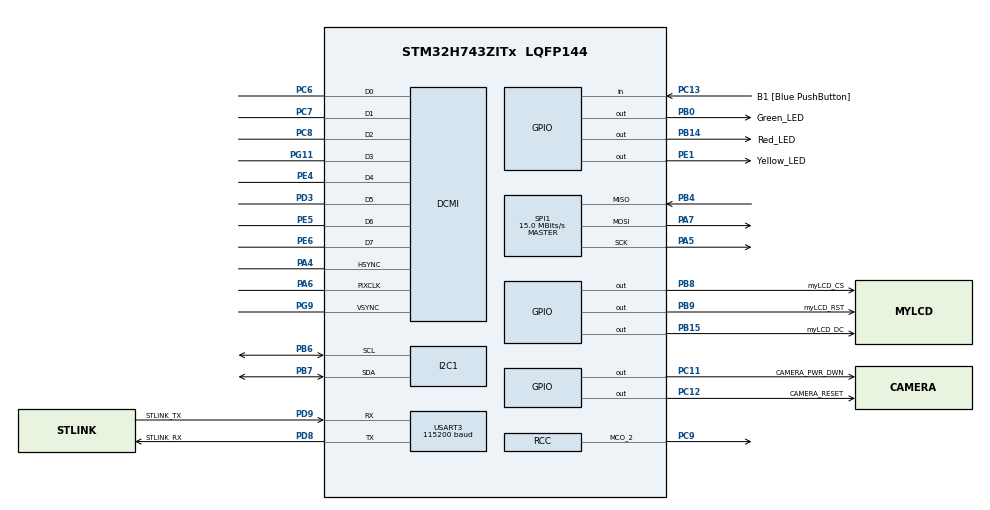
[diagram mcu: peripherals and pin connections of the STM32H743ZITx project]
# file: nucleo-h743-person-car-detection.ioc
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DCMI.ByteSelectMode=DCMI_BSM_ALTERNATE_2
DCMI.HSPolarity=DCMI_HSPOLARITY_LOW
DCMI.PCKPolarity=DCMI_PCKPOLARITY_RISING
DCMI.VSPolarity=DCMI_VSPOLARITY_HIGH
Dma.DCMI.0.Direction=DMA_PERIPH_TO_MEMORY
Dma.DCMI.0.EventEnable=DISABLE
Dma.DCMI.0.FIFOMode=DMA_FIFOMODE_DISABLE
Dma.DCMI.0.Instance=DMA1_Stream1
Dma.DCMI.0.MemDataAlignment=DMA_MDATAALIGN_WORD
Dma.DCMI.0.MemInc=DMA_MINC_ENABLE
Dma.DCMI.0.Mode=DMA_NORMAL
Dma.DCMI.0.PeriphDataAlignment=DMA_PDATAALIGN_WORD
Dma.DCMI.0.PeriphInc=DMA_PINC_DISABLE
Dma.DCMI.0.Polarity=HAL_DMAMUX_REQ_GEN_RISING
Dma.DCMI.0.Priority=DMA_PRIORITY_MEDIUM
Dma.DCMI.0.RequestNumber=1
Dma.DCMI.0.SignalID=NONE
Dma.DCMI.0.SyncEnable=DISABLE
Dma.DCMI.0.SyncPolarity=HAL_DMAMUX_SYNC_NO_EVENT
Dma.DCMI.0.SyncRequestNumber=1
Dma.DCMI.0.SyncSignalID=NONE
Dma.Request0=DCMI
I2C1.Timing=0x307075B1
Mcu.Family=STM32H7
Mcu.Name=STM32H743ZITx
Mcu.Package=LQFP144
NVIC.DCMI_IRQn=true\:0\:0\:false\:false\:true\:true\:true
NVIC.DMA1_Stream1_IRQn=true\:0\:0\:false\:false\:true\:false\:true
NVIC.PriorityGroup=NVIC_PRIORITYGROUP_4
PA4.Mode=Slave_8_bits_External_Synchro
PA4.Signal=DCMI_HSYNC
PA5.Mode=Full_Duplex_Master
PA5.Signal=SPI1_SCK
PA6.Mode=Slave_8_bits_External_Synchro
PA6.Signal=DCMI_PIXCLK
PA7.Mode=Full_Duplex_Master
PA7.Signal=SPI1_MOSI
PB0.GPIO_Label=Green_LED
PB0.Signal=GPIO_Output
PB14.GPIO_Label=Red_LED
PB14.Signal=GPIO_Output
PB15.GPIO_Label=myLCD_DC
PB15.Signal=GPIO_Output
PB4\ (NJTRST).Mode=Full_Duplex_Master
PB4\ (NJTRST).Signal=SPI1_MISO
PB6.GPIO_PuPd=GPIO_PULLUP
PB6.Mode=I2C
PB6.Signal=I2C1_SCL
PB7.GPIO_PuPd=GPIO_PULLUP
PB7.Mode=I2C
PB7.Signal=I2C1_SDA
PB8.GPIO_Label=myLCD_CS
PB8.GPIO_Speed=GPIO_SPEED_FREQ_VERY_HIGH
PB8.Signal=GPIO_Output
PB9.GPIO_Label=myLCD_RST
PB9.Signal=GPIO_Output
PC11.GPIO_Label=CAMERA_PWR_DWN
PC11.Signal=GPIO_Output
PC12.GPIO_Label=CAMERA_RESET
PC12.PinState=GPIO_PIN_SET
PC12.Signal=GPIO_Output
PC13.GPIO_Label=B1 [Blue PushButton]
PC13.Signal=GPIO_Input
PC14-OSC32_IN\ (OSC32_IN).Mode=LSE-External-Oscillator
PC14-OSC32_IN\ (OSC32_IN).Signal=RCC_OSC32_IN
PC15-OSC32_OUT\ (OSC32_OUT).Mode=LSE-External-Oscillator
PC15-OSC32_OUT\ (OSC32_OUT).Signal=RCC_OSC32_OUT
PC6.Mode=Slave_8_bits_External_Synchro
PC6.Signal=DCMI_D0
PC7.Mode=Slave_8_bits_External_Synchro
PC7.Signal=DCMI_D1
PC8.Mode=Slave_8_bits_External_Synchro
PC8.Signal=DCMI_D2
PC9.Mode=Clock-out-2
PC9.Signal=RCC_MCO_2
PD3.Mode=Slave_8_bits_External_Synchro
PD3.Signal=DCMI_D5
PD8.GPIO_Label=STLINK_RX
PD8.Mode=Asynchronous
PD8.Signal=USART3_TX
PD9.GPIO_Label=STLINK_TX
PD9.Mode=Asynchronous
PD9.Signal=USART3_RX
PE1.GPIO_Label=Yellow_LED
PE1.Signal=GPIO_Output
PE4.Mode=Slave_8_bits_External_Synchro
PE4.Signal=DCMI_D4
PE5.Mode=Slave_8_bits_External_Synchro
PE5.Signal=DCMI_D6
PE6.Mode=Slave_8_bits_External_Synchro
PE6.Signal=DCMI_D7
PG11.Mode=Slave_8_bits_External_Synchro
PG11.Signal=DCMI_D3
PG9.Mode=Slave_8_bits_External_Synchro
PG9.Signal=DCMI_VSYNC
PH0-OSC_IN\ (PH0).Mode=HSE-External-Clock-Source
PH0-OSC_IN\ (PH0).Signal=RCC_OSC_IN
PH1-OSC_OUT\ (PH1).Signal=RCC_OSC_OUT
ProjectManager.HeapSize=0x200
ProjectManager.StackSize=0x400
ProjectManager.TargetToolchain=STM32CubeIDE
RCC.ADCFreq_Value=50666666.666666664
RCC.APB1Freq_Value=120000000
RCC.APB2Freq_Value=120000000
RCC.APB3Freq_Value=120000000
RCC.APB4Freq_Value=120000000
RCC.CortexFreq_Value=480000000
RCC.D1PPRE=RCC_APB3_DIV2
RCC.D2PPRE1=RCC_APB1_DIV2
RCC.D2PPRE2=RCC_APB2_DIV2
RCC.D3PPRE=RCC_APB4_DIV2
RCC.DIVM1=1
RCC.DIVM2=1
RCC.DIVN1=120
RCC.DIVN2=19
RCC.DIVP2=3
RCC.HCLKFreq_Value=240000000
RCC.HPRE=RCC_HCLK_DIV2
RCC.HSE_VALUE=8000000
RCC.PLL2FRACN=0
RCC.PLL3FRACN=0
RCC.PLLFRACN=0
RCC.PLLSourceVirtual=RCC_PLLSOURCE_HSE
RCC.RCC_MCODiv2=RCC_MCODIV_15
RCC.SYSCLKFreq_VALUE=480000000
RCC.SYSCLKSource=RCC_SYSCLKSOURCE_PLLCLK
RCC.USBFreq_Value=480000000
SPI1.BaudRatePrescaler=SPI_BAUDRATEPRESCALER_32
SPI1.CalculateBaudRate=15.0 MBits/s
SPI1.DataSize=SPI_DATASIZE_8BIT
SPI1.Direction=SPI_DIRECTION_2LINES
SPI1.Mode=SPI_MODE_MASTER
SPI1.VirtualType=VM_MASTER
TIM2.Period=4294967295
TIM2.Prescaler=240-1
USART3.BaudRate=115200
USART3.VirtualMode-Asynchronous=VM_ASYNC
VP_TIM2_VS_ClockSourceINT.Mode=Internal
board=NUCLEO-H743ZI2

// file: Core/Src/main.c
/* USER CODE BEGIN Header */
/**
  ******************************************************************************
  * @file           : main.c
  * @brief          : Main program body
  ******************************************************************************
  * @attention
  *
  * <h2><center>&copy; Copyright (c) 2020 STMicroelectronics.
  * All rights reserved.</center></h2>
  *
  * This software component is licensed by ST under BSD 3-Clause license,
  * the "License"; You may not use this file except in compliance with the
  * License. You may obtain a copy of the License at:
  *                        opensource.org/licenses/BSD-3-Clause
  *
  ******************************************************************************
  */
/* USER CODE END Header */
#include "main.h"

/* USER CODE BEGIN Includes */
#include  <string.h>
#include "main_functions.h"

/* USER CODE END Includes */

DCMI_HandleTypeDef hdcmi;
DMA_HandleTypeDef hdma_dcmi;

I2C_HandleTypeDef hi2c1;

SPI_HandleTypeDef hspi1;

TIM_HandleTypeDef htim2;

UART_HandleTypeDef huart3;

void SystemClock_Config(void);
static void MX_GPIO_Init(void);
static void MX_DMA_Init(void);
static void MX_USART3_UART_Init(void);
static void MX_DCMI_Init(void);
static void MX_TIM2_Init(void);
static void MX_I2C1_Init(void);
static void MX_SPI1_Init(void);
/* USER CODE BEGIN PFP */
//static void onFrameCallback();
/* USER CODE END PFP */

int main(void)
{

  /* MCU Configuration--------------------------------------------------------*/

  /* Reset of all peripherals, Initializes the Flash interface and the Systick. */
  HAL_Init();

  /* Configure the system clock */
  SystemClock_Config();

  /* Initialize all configured peripherals */
  MX_GPIO_Init();
  MX_DMA_Init();
  MX_USART3_UART_Init();
  MX_DCMI_Init();
  MX_TIM2_Init();
  MX_I2C1_Init();
  MX_SPI1_Init();
  /* USER CODE BEGIN 2 */
  setup(&htim2, &huart3, &hdcmi, &hdma_dcmi, &hi2c1, &hspi1);
  /* USER CODE END 2 */

  /* Infinite loop */
  /* USER CODE BEGIN WHILE */
  while (1)
  {
	  loop(&htim2, &huart3, &hdcmi, &hdma_dcmi, &hi2c1, &hspi1);
    /* USER CODE END WHILE */

  }
}

void SystemClock_Config(void)
{
  RCC_OscInitTypeDef RCC_OscInitStruct = {0};
  RCC_ClkInitTypeDef RCC_ClkInitStruct = {0};
  RCC_PeriphCLKInitTypeDef PeriphClkInitStruct = {0};

  /** Supply configuration update enable
  */
  HAL_PWREx_ConfigSupply(PWR_LDO_SUPPLY);
  /** Configure the main internal regulator output voltage
  */
  __HAL_PWR_VOLTAGESCALING_CONFIG(PWR_REGULATOR_VOLTAGE_SCALE0);

  while(!__HAL_PWR_GET_FLAG(PWR_FLAG_VOSRDY)) {}
  /** Initializes the RCC Oscillators according to the specified parameters
  * in the RCC_OscInitTypeDef structure.
  */
  RCC_OscInitStruct.OscillatorType = RCC_OSCILLATORTYPE_HSE;
  RCC_OscInitStruct.HSEState = RCC_HSE_BYPASS;
  RCC_OscInitStruct.PLL.PLLState = RCC_PLL_ON;
  RCC_OscInitStruct.PLL.PLLSource = RCC_PLLSOURCE_HSE;
  RCC_OscInitStruct.PLL.PLLM = 1;
  RCC_OscInitStruct.PLL.PLLN = 120;
  RCC_OscInitStruct.PLL.PLLP = 2;
  RCC_OscInitStruct.PLL.PLLQ = 2;
  RCC_OscInitStruct.PLL.PLLR = 2;
  RCC_OscInitStruct.PLL.PLLRGE = RCC_PLL1VCIRANGE_3;
  RCC_OscInitStruct.PLL.PLLVCOSEL = RCC_PLL1VCOWIDE;
  RCC_OscInitStruct.PLL.PLLFRACN = 0;
  if (HAL_RCC_OscConfig(&RCC_OscInitStruct) != HAL_OK)
  {
    Error_Handler();
  }
  /** Initializes the CPU, AHB and APB buses clocks
  */
  RCC_ClkInitStruct.ClockType = RCC_CLOCKTYPE_HCLK|RCC_CLOCKTYPE_SYSCLK
                              |RCC_CLOCKTYPE_PCLK1|RCC_CLOCKTYPE_PCLK2
                              |RCC_CLOCKTYPE_D3PCLK1|RCC_CLOCKTYPE_D1PCLK1;
  RCC_ClkInitStruct.SYSCLKSource = RCC_SYSCLKSOURCE_PLLCLK;
  RCC_ClkInitStruct.SYSCLKDivider = RCC_SYSCLK_DIV1;
  RCC_ClkInitStruct.AHBCLKDivider = RCC_HCLK_DIV2;
  RCC_ClkInitStruct.APB3CLKDivider = RCC_APB3_DIV2;
  RCC_ClkInitStruct.APB1CLKDivider = RCC_APB1_DIV2;
  RCC_ClkInitStruct.APB2CLKDivider = RCC_APB2_DIV2;
  RCC_ClkInitStruct.APB4CLKDivider = RCC_APB4_DIV2;

  if (HAL_RCC_ClockConfig(&RCC_ClkInitStruct, FLASH_LATENCY_4) != HAL_OK)
  {
    Error_Handler();
  }
  PeriphClkInitStruct.PeriphClockSelection = RCC_PERIPHCLK_USART3|RCC_PERIPHCLK_SPI1
                              |RCC_PERIPHCLK_I2C1;
  PeriphClkInitStruct.Spi123ClockSelection = RCC_SPI123CLKSOURCE_PLL;
  PeriphClkInitStruct.Usart234578ClockSelection = RCC_USART234578CLKSOURCE_D2PCLK1;
  PeriphClkInitStruct.I2c123ClockSelection = RCC_I2C123CLKSOURCE_D2PCLK1;
  if (HAL_RCCEx_PeriphCLKConfig(&PeriphClkInitStruct) != HAL_OK)
  {
    Error_Handler();
  }
  HAL_RCC_MCOConfig(RCC_MCO2, RCC_MCO2SOURCE_SYSCLK, RCC_MCODIV_15);
}

static void MX_DCMI_Init(void)
{

  hdcmi.Instance = DCMI;
  hdcmi.Init.SynchroMode = DCMI_SYNCHRO_HARDWARE;
  hdcmi.Init.PCKPolarity = DCMI_PCKPOLARITY_RISING;
  hdcmi.Init.VSPolarity = DCMI_VSPOLARITY_HIGH;
  hdcmi.Init.HSPolarity = DCMI_HSPOLARITY_LOW;
  hdcmi.Init.CaptureRate = DCMI_CR_ALL_FRAME;
  hdcmi.Init.ExtendedDataMode = DCMI_EXTEND_DATA_8B;
  hdcmi.Init.JPEGMode = DCMI_JPEG_DISABLE;
  hdcmi.Init.ByteSelectMode = DCMI_BSM_ALTERNATE_2;
  hdcmi.Init.ByteSelectStart = DCMI_OEBS_ODD;
  hdcmi.Init.LineSelectMode = DCMI_LSM_ALL;
  hdcmi.Init.LineSelectStart = DCMI_OELS_ODD;
  if (HAL_DCMI_Init(&hdcmi) != HAL_OK)
  {
    Error_Handler();
  }

}

static void MX_I2C1_Init(void)
{

  hi2c1.Instance = I2C1;
  hi2c1.Init.Timing = 0x307075B1;
  hi2c1.Init.OwnAddress1 = 0;
  hi2c1.Init.AddressingMode = I2C_ADDRESSINGMODE_7BIT;
  hi2c1.Init.DualAddressMode = I2C_DUALADDRESS_DISABLE;
  hi2c1.Init.OwnAddress2 = 0;
  hi2c1.Init.OwnAddress2Masks = I2C_OA2_NOMASK;
  hi2c1.Init.GeneralCallMode = I2C_GENERALCALL_DISABLE;
  hi2c1.Init.NoStretchMode = I2C_NOSTRETCH_DISABLE;
  if (HAL_I2C_Init(&hi2c1) != HAL_OK)
  {
    Error_Handler();
  }
  /** Configure Analogue filter
  */
  if (HAL_I2CEx_ConfigAnalogFilter(&hi2c1, I2C_ANALOGFILTER_ENABLE) != HAL_OK)
  {
    Error_Handler();
  }
  /** Configure Digital filter
  */
  if (HAL_I2CEx_ConfigDigitalFilter(&hi2c1, 0) != HAL_OK)
  {
    Error_Handler();
  }

}

static void MX_SPI1_Init(void)
{

  /* SPI1 parameter configuration*/
  hspi1.Instance = SPI1;
  hspi1.Init.Mode = SPI_MODE_MASTER;
  hspi1.Init.Direction = SPI_DIRECTION_2LINES;
  hspi1.Init.DataSize = SPI_DATASIZE_8BIT;
  hspi1.Init.CLKPolarity = SPI_POLARITY_LOW;
  hspi1.Init.CLKPhase = SPI_PHASE_1EDGE;
  hspi1.Init.NSS = SPI_NSS_SOFT;
  hspi1.Init.BaudRatePrescaler = SPI_BAUDRATEPRESCALER_32;
  hspi1.Init.FirstBit = SPI_FIRSTBIT_MSB;
  hspi1.Init.TIMode = SPI_TIMODE_DISABLE;
  hspi1.Init.CRCCalculation = SPI_CRCCALCULATION_DISABLE;
  hspi1.Init.CRCPolynomial = 0x0;
  hspi1.Init.NSSPMode = SPI_NSS_PULSE_ENABLE;
  hspi1.Init.NSSPolarity = SPI_NSS_POLARITY_LOW;
  hspi1.Init.FifoThreshold = SPI_FIFO_THRESHOLD_01DATA;
  hspi1.Init.TxCRCInitializationPattern = SPI_CRC_INITIALIZATION_ALL_ZERO_PATTERN;
  hspi1.Init.RxCRCInitializationPattern = SPI_CRC_INITIALIZATION_ALL_ZERO_PATTERN;
  hspi1.Init.MasterSSIdleness = SPI_MASTER_SS_IDLENESS_00CYCLE;
  hspi1.Init.MasterInterDataIdleness = SPI_MASTER_INTERDATA_IDLENESS_00CYCLE;
  hspi1.Init.MasterReceiverAutoSusp = SPI_MASTER_RX_AUTOSUSP_DISABLE;
  hspi1.Init.MasterKeepIOState = SPI_MASTER_KEEP_IO_STATE_DISABLE;
  hspi1.Init.IOSwap = SPI_IO_SWAP_DISABLE;
  if (HAL_SPI_Init(&hspi1) != HAL_OK)
  {
    Error_Handler();
  }

}

static void MX_TIM2_Init(void)
{

  TIM_ClockConfigTypeDef sClockSourceConfig = {0};
  TIM_MasterConfigTypeDef sMasterConfig = {0};

  htim2.Instance = TIM2;
  htim2.Init.Prescaler = 240-1;
  htim2.Init.CounterMode = TIM_COUNTERMODE_UP;
  htim2.Init.Period = 4294967295;
  htim2.Init.ClockDivision = TIM_CLOCKDIVISION_DIV1;
  htim2.Init.AutoReloadPreload = TIM_AUTORELOAD_PRELOAD_DISABLE;
  if (HAL_TIM_Base_Init(&htim2) != HAL_OK)
  {
    Error_Handler();
  }
  sClockSourceConfig.ClockSource = TIM_CLOCKSOURCE_INTERNAL;
  if (HAL_TIM_ConfigClockSource(&htim2, &sClockSourceConfig) != HAL_OK)
  {
    Error_Handler();
  }
  sMasterConfig.MasterOutputTrigger = TIM_TRGO_RESET;
  sMasterConfig.MasterSlaveMode = TIM_MASTERSLAVEMODE_DISABLE;
  if (HAL_TIMEx_MasterConfigSynchronization(&htim2, &sMasterConfig) != HAL_OK)
  {
    Error_Handler();
  }

}

static void MX_USART3_UART_Init(void)
{

  huart3.Instance = USART3;
  huart3.Init.BaudRate = 115200;
  huart3.Init.WordLength = UART_WORDLENGTH_8B;
  huart3.Init.StopBits = UART_STOPBITS_1;
  huart3.Init.Parity = UART_PARITY_NONE;
  huart3.Init.Mode = UART_MODE_TX_RX;
  huart3.Init.HwFlowCtl = UART_HWCONTROL_NONE;
  huart3.Init.OverSampling = UART_OVERSAMPLING_16;
  huart3.Init.OneBitSampling = UART_ONE_BIT_SAMPLE_DISABLE;
  huart3.Init.ClockPrescaler = UART_PRESCALER_DIV1;
  huart3.AdvancedInit.AdvFeatureInit = UART_ADVFEATURE_NO_INIT;
  if (HAL_UART_Init(&huart3) != HAL_OK)
  {
    Error_Handler();
  }
  if (HAL_UARTEx_SetTxFifoThreshold(&huart3, UART_TXFIFO_THRESHOLD_1_8) != HAL_OK)
  {
    Error_Handler();
  }
  if (HAL_UARTEx_SetRxFifoThreshold(&huart3, UART_RXFIFO_THRESHOLD_1_8) != HAL_OK)
  {
    Error_Handler();
  }
  if (HAL_UARTEx_DisableFifoMode(&huart3) != HAL_OK)
  {
    Error_Handler();
  }

}

static void MX_DMA_Init(void)
{

  /* DMA controller clock enable */
  __HAL_RCC_DMA1_CLK_ENABLE();

  /* DMA interrupt init */
  /* DMA1_Stream1_IRQn interrupt configuration */
  HAL_NVIC_SetPriority(DMA1_Stream1_IRQn, 0, 0);
  HAL_NVIC_EnableIRQ(DMA1_Stream1_IRQn);

}

static void MX_GPIO_Init(void)
{
  GPIO_InitTypeDef GPIO_InitStruct = {0};

  /* GPIO Ports Clock Enable */
  __HAL_RCC_GPIOE_CLK_ENABLE();
  __HAL_RCC_GPIOC_CLK_ENABLE();
  __HAL_RCC_GPIOH_CLK_ENABLE();
  __HAL_RCC_GPIOA_CLK_ENABLE();
  __HAL_RCC_GPIOB_CLK_ENABLE();
  __HAL_RCC_GPIOD_CLK_ENABLE();
  __HAL_RCC_GPIOG_CLK_ENABLE();

  /*Configure GPIO pin Output Level */
  HAL_GPIO_WritePin(GPIOB, Green_LED_Pin|Red_LED_Pin|myLCD_DC_Pin|myLCD_CS_Pin
                          |myLCD_RST_Pin, GPIO_PIN_RESET);

  /*Configure GPIO pin Output Level */
  HAL_GPIO_WritePin(CAMERA_PWR_DWN_GPIO_Port, CAMERA_PWR_DWN_Pin, GPIO_PIN_RESET);

  /*Configure GPIO pin Output Level */
  HAL_GPIO_WritePin(CAMERA_RESET_GPIO_Port, CAMERA_RESET_Pin, GPIO_PIN_SET);

  /*Configure GPIO pin Output Level */
  HAL_GPIO_WritePin(Yellow_LED_GPIO_Port, Yellow_LED_Pin, GPIO_PIN_RESET);

  /*Configure GPIO pin : B1_Pin */
  GPIO_InitStruct.Pin = B1_Pin;
  GPIO_InitStruct.Mode = GPIO_MODE_INPUT;
  GPIO_InitStruct.Pull = GPIO_NOPULL;
  HAL_GPIO_Init(B1_GPIO_Port, &GPIO_InitStruct);

  /*Configure GPIO pins : Green_LED_Pin Red_LED_Pin myLCD_DC_Pin myLCD_RST_Pin */
  GPIO_InitStruct.Pin = Green_LED_Pin|Red_LED_Pin|myLCD_DC_Pin|myLCD_RST_Pin;
  GPIO_InitStruct.Mode = GPIO_MODE_OUTPUT_PP;
  GPIO_InitStruct.Pull = GPIO_NOPULL;
  GPIO_InitStruct.Speed = GPIO_SPEED_FREQ_LOW;
  HAL_GPIO_Init(GPIOB, &GPIO_InitStruct);

  /*Configure GPIO pin : PC9 */
  GPIO_InitStruct.Pin = GPIO_PIN_9;
  GPIO_InitStruct.Mode = GPIO_MODE_AF_PP;
  GPIO_InitStruct.Pull = GPIO_NOPULL;
  GPIO_InitStruct.Speed = GPIO_SPEED_FREQ_LOW;
  GPIO_InitStruct.Alternate = GPIO_AF0_MCO;
  HAL_GPIO_Init(GPIOC, &GPIO_InitStruct);

  /*Configure GPIO pins : CAMERA_PWR_DWN_Pin CAMERA_RESET_Pin */
  GPIO_InitStruct.Pin = CAMERA_PWR_DWN_Pin|CAMERA_RESET_Pin;
  GPIO_InitStruct.Mode = GPIO_MODE_OUTPUT_PP;
  GPIO_InitStruct.Pull = GPIO_NOPULL;
  GPIO_InitStruct.Speed = GPIO_SPEED_FREQ_LOW;
  HAL_GPIO_Init(GPIOC, &GPIO_InitStruct);

  /*Configure GPIO pin : myLCD_CS_Pin */
  GPIO_InitStruct.Pin = myLCD_CS_Pin;
  GPIO_InitStruct.Mode = GPIO_MODE_OUTPUT_PP;
  GPIO_InitStruct.Pull = GPIO_NOPULL;
  GPIO_InitStruct.Speed = GPIO_SPEED_FREQ_VERY_HIGH;
  HAL_GPIO_Init(myLCD_CS_GPIO_Port, &GPIO_InitStruct);

  /*Configure GPIO pin : Yellow_LED_Pin */
  GPIO_InitStruct.Pin = Yellow_LED_Pin;
  GPIO_InitStruct.Mode = GPIO_MODE_OUTPUT_PP;
  GPIO_InitStruct.Pull = GPIO_NOPULL;
  GPIO_InitStruct.Speed = GPIO_SPEED_FREQ_LOW;
  HAL_GPIO_Init(Yellow_LED_GPIO_Port, &GPIO_InitStruct);

}

/* USER CODE BEGIN 4 */

// Debug via UART for Tensorflow library
void DebugLog(const char *s){
	HAL_UART_Transmit(&huart3, (uint8_t *) s, strlen(s), 100);
}

/* USER CODE END 4 */

void Error_Handler(void)
{
}

/************************ (C) COPYRIGHT STMicroelectronics *****END OF FILE****/
